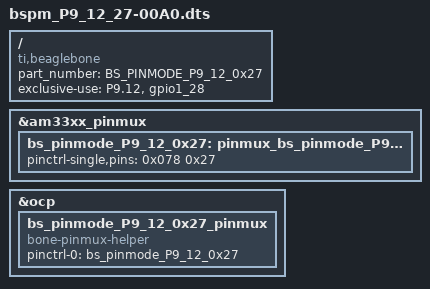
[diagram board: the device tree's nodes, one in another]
/dts-v1/;
/plugin/;

/{
  compatible = "ti,beaglebone", "ti,beaglebone-black";
  part_number = "BS_PINMODE_P9_12_0x27";

  exclusive-use =
    "P9.12",
    "gpio1_28";

  fragment@0 {
    target = <&am33xx_pinmux>;
    __overlay__ {
      bs_pinmode_P9_12_0x27: pinmux_bs_pinmode_P9_12_0x27 {
        pinctrl-single,pins = <0x078 0x27>;
      };
    };
  };

  fragment@1 {
    target = <&ocp>;
    __overlay__ {
      bs_pinmode_P9_12_0x27_pinmux {
        compatible = "bone-pinmux-helper";
        status = "okay";
        pinctrl-names = "default";
        pinctrl-0 = <&bs_pinmode_P9_12_0x27>;
      };
    };
  };
};

